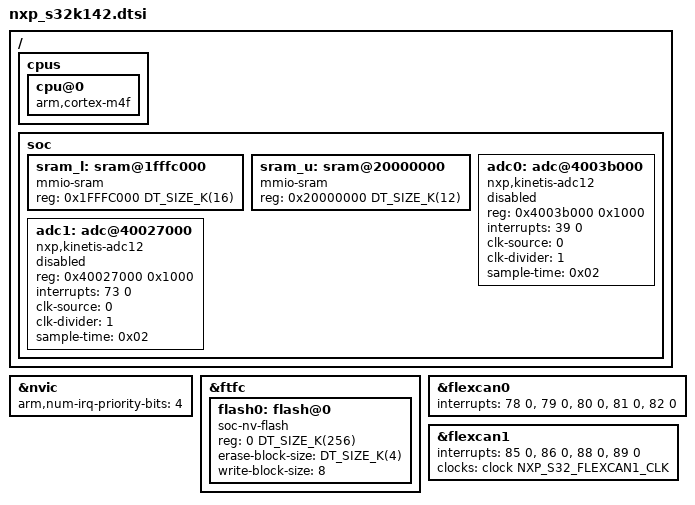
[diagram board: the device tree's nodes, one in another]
/*
 * Copyright 2023 NXP
 *
 * SPDX-License-Identifier: Apache-2.0
 */

 #include <dt-bindings/clock/nxp_s32k142_clock.h>
 #include <nxp/nxp_s32k1xx.dtsi>
 
 / {
     cpus {
         cpu@0 {
             compatible = "arm,cortex-m4f";
         };
     };



    /*
    adc1: adc@40027000 {
        compatible = "nxp,kinetis-adc12";
        reg = <0x40027000 0x1000>;
        interrupts = <73 0>;
        clocks = <&pcc 0x9c KINETIS_PCC_SRC_FIRC_ASYNC>;
        clk-source = <0>;
        clk-divider = <1>;
        status = "disabled";
        #io-channel-cells = <1>;
    };
    */
     soc {
         /*
          * SRAM_L and SRAM_U ranges form a contiguous block but misaligned
          * and burst accesses cannot occur across the 0x20000000 boundary
          * that separates the two SRAM arrays. Hence, treat the two arrays
          * as separate memory ranges.
          */
         sram_l: sram@1fffc000 {
             compatible = "mmio-sram";
             reg = <0x1FFFC000 DT_SIZE_K(16)>;
         };
 
         sram_u: sram@20000000 {
             compatible = "mmio-sram";
             reg = <0x20000000 DT_SIZE_K(12)>;
         };
         adc0: adc@4003b000 {
            compatible = "nxp,kinetis-adc12";
            reg = <0x4003b000 0x1000>;
            interrupts = <39 0>;
            clk-source = <0>;
            clk-divider = <1>;
            status = "disabled";
            #io-channel-cells = <1>;
            sample-time = <0x02>;
        };
        adc1: adc@40027000 {
            compatible = "nxp,kinetis-adc12";
            reg = <0x40027000 0x1000>;
            interrupts = <73 0>;
            clk-source = <0>;
            clk-divider = <1>;
            status = "disabled";
            #io-channel-cells = <1>;
            sample-time = <0x02>;
        };
     };
 };
/delete-node/ &ftm4;
/delete-node/ &ftm5;
/delete-node/ &flexcan2;
/delete-node/ &lpspi2;
/delete-node/ &lpuart2;

 &nvic {
     arm,num-irq-priority-bits = <4>;
 };
 
 &ftfc {
     flash0: flash@0 {
         compatible = "soc-nv-flash";
         reg = <0 DT_SIZE_K(256)>;
         erase-block-size = <DT_SIZE_K(4)>;
         write-block-size = <8>;
     };
 };
 
 
 &flexcan0 {
     interrupts = <78 0>, <79 0>, <80 0>, <81 0>, <82 0>;
     interrupt-names = "warning", "error", "wake-up", "mb-0-15", "mb-16-31";
 };
 
 &flexcan1 {
     interrupts = <85 0>, <86 0>, <88 0>, <89 0>;
     interrupt-names = "warning", "error", "mb-0-15", "mb-16-31";
     clocks = <&clock NXP_S32_FLEXCAN1_CLK>;
 };
